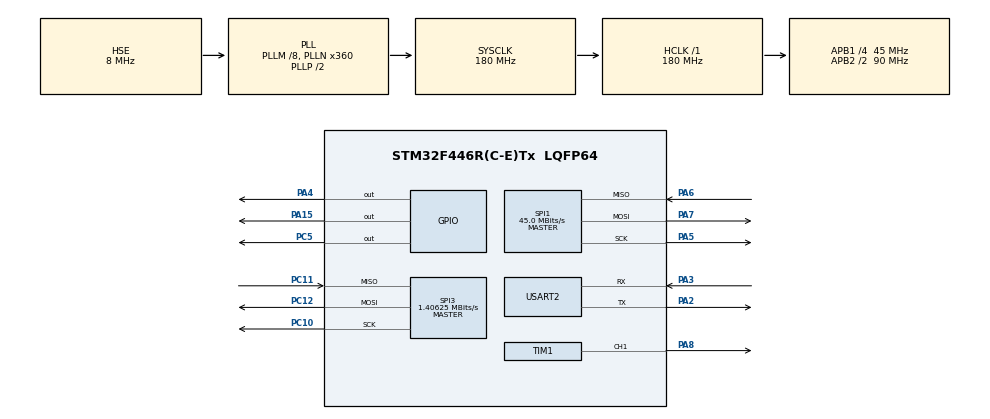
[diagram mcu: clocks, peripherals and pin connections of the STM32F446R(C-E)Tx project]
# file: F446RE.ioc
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Mcu.Family=STM32F4
Mcu.Name=STM32F446R(C-E)Tx
Mcu.Package=LQFP64
NVIC.PriorityGroup=NVIC_PRIORITYGROUP_4
NVIC.TIM1_UP_TIM10_IRQn=true\:0\:0\:false\:false\:true\:true\:true\:true
PA13.Mode=Serial_Wire
PA13.Signal=SYS_JTMS-SWDIO
PA14.Mode=Serial_Wire
PA14.Signal=SYS_JTCK-SWCLK
PA15.Signal=GPIO_Output
PA2.Mode=Asynchronous
PA2.Signal=USART2_TX
PA3.Mode=Asynchronous
PA3.Signal=USART2_RX
PA4.Signal=GPIO_Output
PA5.Mode=Full_Duplex_Master
PA5.Signal=SPI1_SCK
PA6.Mode=Full_Duplex_Master
PA6.Signal=SPI1_MISO
PA7.Mode=Full_Duplex_Master
PA7.Signal=SPI1_MOSI
PA8.Signal=S_TIM1_CH1
PC10.Mode=Full_Duplex_Master
PC10.Signal=SPI3_SCK
PC11.Mode=Full_Duplex_Master
PC11.Signal=SPI3_MISO
PC12.Mode=Full_Duplex_Master
PC12.Signal=SPI3_MOSI
PC5.Signal=GPIO_Output
PH0-OSC_IN.Mode=HSE-External-Oscillator
PH0-OSC_IN.Signal=RCC_OSC_IN
PH1-OSC_OUT.Mode=HSE-External-Oscillator
PH1-OSC_OUT.Signal=RCC_OSC_OUT
ProjectManager.HeapSize=0x200
ProjectManager.StackSize=0x400
ProjectManager.TargetToolchain=STM32CubeIDE
RCC.AHBFreq_Value=180000000
RCC.APB1CLKDivider=RCC_HCLK_DIV4
RCC.APB1Freq_Value=45000000
RCC.APB1TimFreq_Value=90000000
RCC.APB2CLKDivider=RCC_HCLK_DIV2
RCC.APB2Freq_Value=90000000
RCC.APB2TimFreq_Value=180000000
RCC.CodegenConfigPeriph=true
RCC.CortexFreq_Value=180000000
RCC.HCLKFreq_Value=180000000
RCC.HSE_VALUE=8000000
RCC.LSE_Drive_CapabilityArg=+LSE_Drive_Capability
RCC.PLLM=8
RCC.PLLN=360
RCC.PLLSourceVirtual=RCC_PLLSOURCE_HSE
RCC.SYSCLKFreq_VALUE=180000000
RCC.SYSCLKSource=RCC_SYSCLKSOURCE_PLLCLK
RCC.USBFreq_Value=180000000
RCC.VCOOutputFreq_Value=360000000
SH.S_TIM1_CH1.0=TIM1_CH1,PWM Generation1 CH1
SPI1.CalculateBaudRate=45.0 MBits/s
SPI1.DataSize=SPI_DATASIZE_16BIT
SPI1.Direction=SPI_DIRECTION_2LINES
SPI1.Mode=SPI_MODE_MASTER
SPI1.VirtualType=VM_MASTER
SPI3.BaudRatePrescaler=SPI_BAUDRATEPRESCALER_32
SPI3.CLKPhase=SPI_PHASE_2EDGE
SPI3.CalculateBaudRate=1.40625 MBits/s
SPI3.DataSize=SPI_DATASIZE_16BIT
SPI3.Direction=SPI_DIRECTION_2LINES
SPI3.Mode=SPI_MODE_MASTER
SPI3.VirtualType=VM_MASTER
TIM1.AutoReloadPreload=TIM_AUTORELOAD_PRELOAD_ENABLE
TIM1.Channel-PWM\ Generation1\ CH1=TIM_CHANNEL_1
TIM1.CounterMode=TIM_COUNTERMODE_CENTERALIGNED1
TIM1.OCPolarity_1=TIM_OCPOLARITY_LOW
TIM1.Period=0x8CA
TIM1.Prescaler=0
TIM1.RepetitionCounter=1
USART2.VirtualMode=VM_ASYNC
VP_TIM1_VS_ClockSourceINT.Mode=Internal
board=custom

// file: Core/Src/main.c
/* USER CODE BEGIN Header */
/**
  ******************************************************************************
  * @file           : main.c
  * @brief          : Main program body
  ******************************************************************************
  * @attention
  *
  * Copyright (c) 2025 STMicroelectronics.
  * All rights reserved.
  *
  * This software is licensed under terms that can be found in the LICENSE file
  * in the root directory of this software component.
  * If no LICENSE file comes with this software, it is provided AS-IS.
  *
  ******************************************************************************
  */
/* USER CODE END Header */
#include "main.h"
#include "spi.h"
#include "tim.h"
#include "usart.h"
#include "gpio.h"

void SystemClock_Config(void);

int main(void)
{

  /* MCU Configuration--------------------------------------------------------*/

  /* Reset of all peripherals, Initializes the Flash interface and the Systick. */
  HAL_Init();

  /* Configure the system clock */
  SystemClock_Config();

  /* Initialize all configured peripherals */
  MX_GPIO_Init();
  MX_TIM1_Init();
  MX_SPI1_Init();
  MX_SPI3_Init();
  MX_USART2_UART_Init();
  /* USER CODE BEGIN 2 */
  HAL_TIM_PWM_Start(&htim1, TIM_CHANNEL_1);
  __HAL_TIM_SET_COMPARE(&htim1, TIM_CHANNEL_1, htim1.Init.Period/4);
  HAL_TIM_Base_Start_IT(&htim1);
  /* USER CODE END 2 */

  /* Infinite loop */
  while (1)
  {

    /* USER CODE BEGIN 3 */
//	  HAL_GPIO_WritePin(GPIOC, GPIO_PIN_5, GPIO_PIN_SET);
//	  HAL_Delay(1000); // wait for 1 sec
//
//	  HAL_GPIO_WritePin(GPIOC, GPIO_PIN_5, GPIO_PIN_RESET);
//	  HAL_Delay(1000); // wait for 1 se
  }
  /* USER CODE END 3 */
}

void SystemClock_Config(void)
{
  RCC_OscInitTypeDef RCC_OscInitStruct = {0};
  RCC_ClkInitTypeDef RCC_ClkInitStruct = {0};

  /** Configure the main internal regulator output voltage
  */
  __HAL_RCC_PWR_CLK_ENABLE();
  __HAL_PWR_VOLTAGESCALING_CONFIG(PWR_REGULATOR_VOLTAGE_SCALE1);

  /** Initializes the RCC Oscillators according to the specified parameters
  * in the RCC_OscInitTypeDef structure.
  */
  RCC_OscInitStruct.OscillatorType = RCC_OSCILLATORTYPE_HSE;
  RCC_OscInitStruct.HSEState = RCC_HSE_ON;
  RCC_OscInitStruct.PLL.PLLState = RCC_PLL_ON;
  RCC_OscInitStruct.PLL.PLLSource = RCC_PLLSOURCE_HSE;
  RCC_OscInitStruct.PLL.PLLM = 8;
  RCC_OscInitStruct.PLL.PLLN = 360;
  RCC_OscInitStruct.PLL.PLLP = RCC_PLLP_DIV2;
  RCC_OscInitStruct.PLL.PLLQ = 2;
  RCC_OscInitStruct.PLL.PLLR = 2;
  if (HAL_RCC_OscConfig(&RCC_OscInitStruct) != HAL_OK)
  {
    Error_Handler();
  }

  /** Activate the Over-Drive mode
  */
  if (HAL_PWREx_EnableOverDrive() != HAL_OK)
  {
    Error_Handler();
  }

  /** Initializes the CPU, AHB and APB buses clocks
  */
  RCC_ClkInitStruct.ClockType = RCC_CLOCKTYPE_HCLK|RCC_CLOCKTYPE_SYSCLK
                              |RCC_CLOCKTYPE_PCLK1|RCC_CLOCKTYPE_PCLK2;
  RCC_ClkInitStruct.SYSCLKSource = RCC_SYSCLKSOURCE_PLLCLK;
  RCC_ClkInitStruct.AHBCLKDivider = RCC_SYSCLK_DIV1;
  RCC_ClkInitStruct.APB1CLKDivider = RCC_HCLK_DIV4;
  RCC_ClkInitStruct.APB2CLKDivider = RCC_HCLK_DIV2;

  if (HAL_RCC_ClockConfig(&RCC_ClkInitStruct, FLASH_LATENCY_5) != HAL_OK)
  {
    Error_Handler();
  }
}

void Error_Handler(void)
{
  __disable_irq();
  while (1)
  {
  }
}
